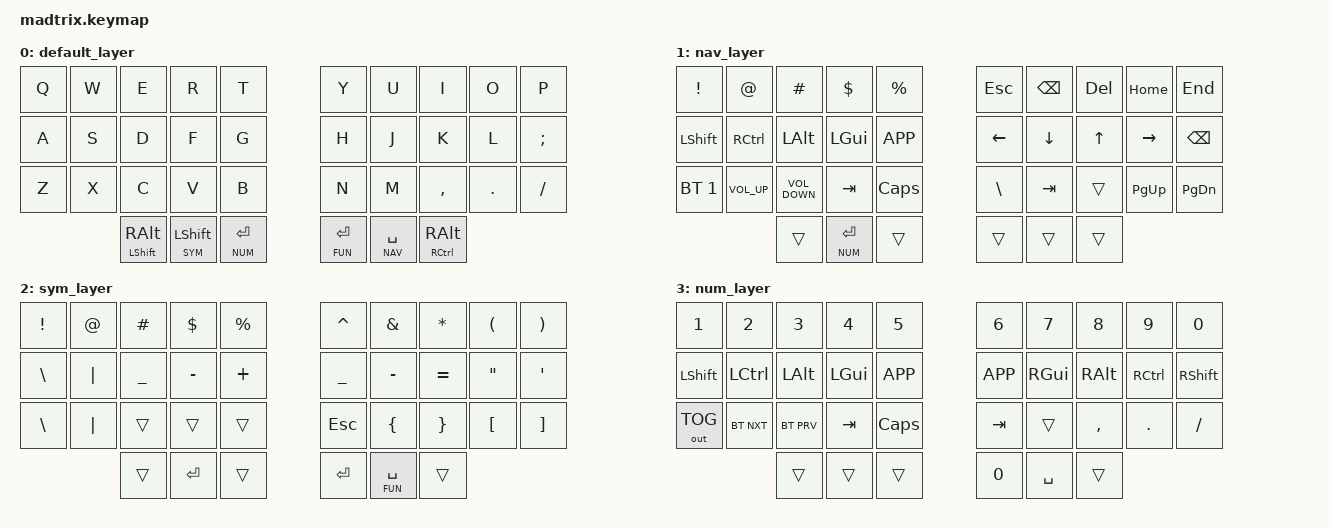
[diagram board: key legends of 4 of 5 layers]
/*
 * Copyright (c) 2020 The ZMK Contributors
 ***
 * SPDX-License-Identifier: MIT
 */ 
#include <behaviors.dtsi>
#include <dt-bindings/zmk/keys.h>
#include <dt-bindings/zmk/bt.h>
#include <dt-bindings/zmk/ext_power.h>
#include <dt-bindings/zmk/outputs.h>
/ {
    macros {
        bl_work_monitor: bl_work_monitor {
            label = "ZM_bl_work_monitor";
            compatible = "zmk,behavior-macro";
            #binding-cells = <0>;
            bindings
                = <&bt BT_SEL 2>
                , <&kp F4>
                , <&bt BT_SEL 0>
                ;
        };
        bl_pc_monitor: bl_pc_monitor {
            label = "ZM_bl_pc_monitor";
            compatible = "zmk,behavior-macro";
            #binding-cells = <0>;
            bindings
                = <&bt BT_SEL 2>
                , <&kp F3>
                , <&bt BT_SEL 1>
                ;
        };
        bl_work: bl_work {
            label = "ZM_bl_work";
            compatible = "zmk,behavior-macro";
            #binding-cells = <0>;
            bindings
                = <&bt BT_SEL 2>
                , <&kp F2>
                , <&bt BT_SEL 0>
                ;
        };
        bl_PC: bl_PC {
            label = "ZM_bl_PC";
            compatible = "zmk,behavior-macro";
            #binding-cells = <0>;
            bindings
                = <&bt BT_SEL 2>
                , <&kp F1>
                , <&bt BT_SEL 1>
                ;
        };
        bl_PI: bl_PI {
            label = "ZM_bl_PI";
            compatible = "zmk,behavior-macro";
            #binding-cells = <0>;
            bindings
                = <&bt BT_SEL 2>
                , <&kp F5 >
                ;
        };

    };
};

&sk {
    release-after-ms = <2000>;
    quick-release;
    /delete-property/ ignore-modifiers;
};
&kscan0 {
    debounce-press-ms = <2>;
    debounce-release-ms = <3>;
};

/{
behaviors {
        ss: sym_shift {
            compatible = "zmk,behavior-hold-tap";
            label = "Sym_Shift";
            #binding-cells = <2>;
            flavor = "balanced";            
            tapping-term-ms = <165>;
            require-prior-idle-ms = <50>;
            retro-tap;
            bindings = <&mo>, <&sk>;
        };
        nv: nav_space {
            compatible = "zmk,behavior-hold-tap";
            label = "Nav_Space";
            #binding-cells = <2>;
            flavor = "balanced";
            tapping-term-ms = <200>;
            require-prior-idle-ms = <50>;            
            //hold-trigger-key-positions = <1 2 3 4 5 6 7 10 11 12 13 14 15 16 17 18 23 31>;
            retro-tap;
            bindings = <&mo>, <&kp>;

        };
       
        ca: control_alt {
            compatible = "zmk,behavior-hold-tap";
            label = "Control_Alt";
            #binding-cells = <2>;
            tapping-term-ms = <230>;
            flavor = "tap-preferred";
            bindings = <&kp>, <&sk>;
        };
    };
};

#define NAV 1
#define SYM 2
#define NUM 3
#define FUN 4
&lt {
    flavor = "balanced";
    tapping-term-ms = <165>;
    require-prior-idle-ms = <125>;
    retro-tap;
};
/{
        keymap {
                compatible = "zmk,keymap";
                default_layer {
//---------------------------------------------------------------------------------------
// |  Q  |  W  |  E  |  R  |  T   |   |  Y  |  U   |  I  |  O  |  P  |
// |  A  |  S  |  D  |  F  |  G   |   |  H  |  J   |  K  |  L  |  ;  |
// |  Z  |  X  |  C  |  V  |  B   |   |  N  |  M   |  ,  |  .  |  /  |
//             | GUI | NAV | SHFT |   | SPC | SYM  | ALT |
                        bindings = <
   &kp Q &kp W &kp E &kp R &kp T   &kp Y &kp U  &kp I &kp O &kp P
   &kp A &kp S &kp D &kp F  &kp G   &kp H &kp J &kp K &kp L &kp SEMI  
   &kp Z &kp X &kp C &kp V &kp B   &kp N &kp M  &kp COMMA &kp DOT &kp FSLH
         &ca LSHIFT RALT  &ss SYM LSHIFT &lt NUM RET &lt FUN RET  &nv NAV SPACE &ca RCTRL RALT
                        >;
                };
                nav_layer {
// -----------------------------------------------------------------------------------------
// |BTCLR|     | ESC |  ~   |     |   | TAB | BSPC |  DEL | HOME | END  |
// | BT1 | GUI | ALT | CTRL | NUM |   |LEFT | DOWN |  UP  | RIGHT| 
// | BT2 |     |     |      |     |   |  \  | ENT  |      |     |      |
//             |     |      |     |   |     |      |      |
                        bindings = <
   &kp EXCL     &kp AT          &kp HASH          &kp DLLR      &kp PRCNT     &kp ESC      &kp BSPC  &kp DEL &kp HOME  &kp END
   &kp LSHFT    &kp RCTRL       &kp LALT          &kp LGUI      &kp K_APP     &kp LEFT  &kp DOWN  &kp UP  &kp RIGHT &kp BSPC
   &bt BT_SEL 1 &kp C_VOLUME_UP &kp C_VOLUME_DOWN &kp TAB       &kp CAPSLOCK  &kp BSLH  &kp TAB   &trans  &kp PAGE_UP    &kp PAGE_DOWN
                                &trans            &lt NUM RET   &trans        &trans    &trans    &trans
                        >;
                };
                sym_layer {
// -----------------------------------------------------------------------------------------
// |  !  |  @  |  #  |  $  |  %  |   |  ^  |  &  |  *  |  (  |  )  |
// |     |     |     |     |     |   |  -  |  =  |  {  |  }  | "|" |
// |     |     |     |     |     |   |  _  |  +  |  [  |  ]  |  \  |
//             | GUI |     | SPC |   | ENT |     | ALT |
                        bindings = <
   &kp EXCL  &kp AT    &kp HASH  &kp DLLR  &kp PRCNT   &kp CARET &kp AMPS  &kp ASTERISK &kp LPAR &kp RPAR
   &kp BSLH  &kp PIPE  &kp UNDER &kp MINUS &kp PLUS    &kp UNDER &kp MINUS &kp EQUAL       &kp DQT  &kp SQT
   &kp BSLH  &kp PIPE  &trans    &trans    &trans      &kp ESC   &kp LBRC  &kp RBRC        &kp LBKT &kp RBKT
                       &trans &kp ENTER &trans   &kp RET   &lt FUN SPACE    &trans
                        >;
                };
// This layer is unreachable until "tri layer state" is sorted out.
// Leaving it here for completeness.
                num_layer {
// -----------------------------------------------------------------------------------------
// |     |     |     |     |     |   |  A  |  7  |  8  |  9  |  D  |
// |     |     |     |     |     |   |  B  |  4  |  5  |  6  |  E  |
// |     |     |     |     |     |   |  C  |  1  |  2  |  3  |  F  |
//             |     |     |     |   |  0  |  .  |     |
                        bindings = <
   &kp N1           &kp N2           &kp N3            &kp N4        &kp N5        &kp N6    &kp N7   &kp N8    &kp N9    &kp N0
   &kp LSHFT        &kp LCTRL        &kp LALT          &kp LGUI      &kp K_APP     &kp K_APP &kp RGUI &kp RALT  &kp RCTRL &kp RSHFT
   &out OUT_TOG     &bt BT_NXT       &bt BT_PRV        &kp TAB       &kp CAPSLOCK  &kp TAB   &trans    &kp COMMA &kp DOT   &kp FSLH
                    &trans           &trans            &trans        &kp N0        &kp SPACE &trans
                        >;
                };
                        Test_layer {
// -----------------------------------------------------------------------------------------
// |     |     |     |     |     |   |  A  |  7  |  8  |  9  |  D  |
// |     |     |     |     |     |   |  B  |  4  |  5  |  6  |  E  |
// |     |     |     |     |     |   |  C  |  1  |  2  |  3  |  F  |
//             |     |     |     |   |  0  |  .  |     |
                        bindings = <
   &kp F1           &kp F2          &kp F3      &kp F4    &kp F5 &kp F6    &kp F7   &kp F8      &kp F9    &kp F10
   &kp F11          &kp F12         &kp LALT    &kp LGUI  &kp K_APP &kp LGUI &kp LALT    &kp LCTRL &kp LSHFT 
   &bl_work_monitor &bl_pc_monitor  &bl_work    &bl_PC    &bl_PI &ext_power EP_TOG    &trans   &bootloader &trans    &bt BT_CLR 
                                    &trans      &trans    &trans &trans    &trans  &trans
                        >;
                };
                
        };
};
